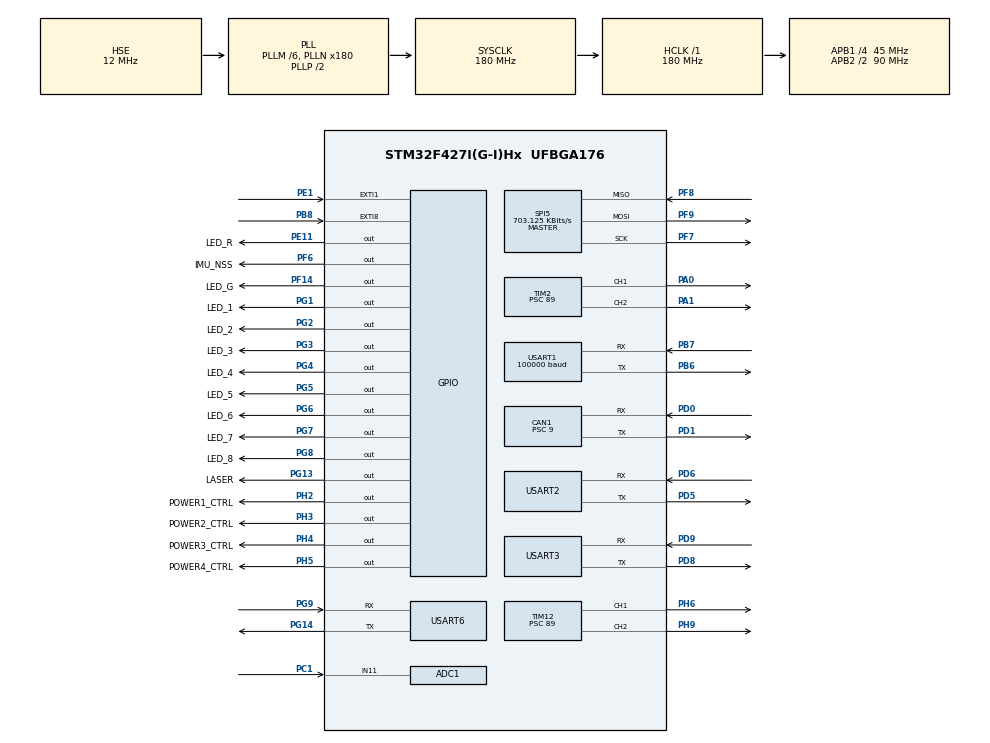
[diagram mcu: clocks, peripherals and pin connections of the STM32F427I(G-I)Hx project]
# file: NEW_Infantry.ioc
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ADC1.Channel-0\#ChannelRegularConversion=ADC_CHANNEL_11
ADC1.NbrOfConversionFlag=1
ADC1.Rank-0\#ChannelRegularConversion=1
ADC1.SamplingTime-0\#ChannelRegularConversion=ADC_SAMPLETIME_3CYCLES
ADC1.master=1
CAN1.BS1=CAN_BS1_2TQ
CAN1.BS2=CAN_BS2_2TQ
CAN1.CalculateTimeQuantum=200.0
CAN1.Prescaler=9
CAN1.TXFP=ENABLE
Dma.Request0=USART1_RX
Dma.Request1=USART3_RX
Dma.Request2=USART6_RX
Dma.Request3=USART6_TX
Dma.USART1_RX.0.Direction=DMA_PERIPH_TO_MEMORY
Dma.USART1_RX.0.FIFOMode=DMA_FIFOMODE_DISABLE
Dma.USART1_RX.0.Instance=DMA2_Stream2
Dma.USART1_RX.0.MemDataAlignment=DMA_MDATAALIGN_BYTE
Dma.USART1_RX.0.MemInc=DMA_MINC_ENABLE
Dma.USART1_RX.0.Mode=DMA_NORMAL
Dma.USART1_RX.0.PeriphDataAlignment=DMA_PDATAALIGN_BYTE
Dma.USART1_RX.0.PeriphInc=DMA_PINC_DISABLE
Dma.USART1_RX.0.Priority=DMA_PRIORITY_MEDIUM
Dma.USART3_RX.1.Direction=DMA_PERIPH_TO_MEMORY
Dma.USART3_RX.1.FIFOMode=DMA_FIFOMODE_DISABLE
Dma.USART3_RX.1.Instance=DMA1_Stream1
Dma.USART3_RX.1.MemDataAlignment=DMA_MDATAALIGN_BYTE
Dma.USART3_RX.1.MemInc=DMA_MINC_ENABLE
Dma.USART3_RX.1.Mode=DMA_NORMAL
Dma.USART3_RX.1.PeriphDataAlignment=DMA_PDATAALIGN_BYTE
Dma.USART3_RX.1.PeriphInc=DMA_PINC_DISABLE
Dma.USART3_RX.1.Priority=DMA_PRIORITY_LOW
Dma.USART6_RX.2.Direction=DMA_PERIPH_TO_MEMORY
Dma.USART6_RX.2.FIFOMode=DMA_FIFOMODE_DISABLE
Dma.USART6_RX.2.Instance=DMA2_Stream1
Dma.USART6_RX.2.MemDataAlignment=DMA_MDATAALIGN_BYTE
Dma.USART6_RX.2.MemInc=DMA_MINC_ENABLE
Dma.USART6_RX.2.Mode=DMA_NORMAL
Dma.USART6_RX.2.PeriphDataAlignment=DMA_PDATAALIGN_BYTE
Dma.USART6_RX.2.PeriphInc=DMA_PINC_DISABLE
Dma.USART6_RX.2.Priority=DMA_PRIORITY_LOW
Dma.USART6_TX.3.Direction=DMA_MEMORY_TO_PERIPH
Dma.USART6_TX.3.FIFOMode=DMA_FIFOMODE_DISABLE
Dma.USART6_TX.3.Instance=DMA2_Stream6
Dma.USART6_TX.3.MemDataAlignment=DMA_MDATAALIGN_BYTE
Dma.USART6_TX.3.MemInc=DMA_MINC_ENABLE
Dma.USART6_TX.3.Mode=DMA_NORMAL
Dma.USART6_TX.3.PeriphDataAlignment=DMA_PDATAALIGN_BYTE
Dma.USART6_TX.3.PeriphInc=DMA_PINC_DISABLE
Dma.USART6_TX.3.Priority=DMA_PRIORITY_LOW
FREERTOS.INCLUDE_vTaskDelayUntil=1
FREERTOS.Tasks01=defaultTask,0,128,StartDefaultTask,Default,NULL
FREERTOS.configUSE_TIMERS=0
Mcu.Family=STM32F4
Mcu.Name=STM32F427I(G-I)Hx
Mcu.Package=UFBGA176
NVIC.CAN1_RX0_IRQn=true\:4\:0\:true\:false\:true\:false\:true\:true
NVIC.DMA1_Stream1_IRQn=true\:5\:0\:false\:false\:true\:true\:false\:true
NVIC.DMA2_Stream1_IRQn=true\:5\:0\:false\:false\:true\:true\:false\:true
NVIC.DMA2_Stream2_IRQn=true\:5\:0\:false\:false\:true\:true\:false\:true
NVIC.DMA2_Stream6_IRQn=true\:5\:0\:false\:false\:true\:true\:false\:true
NVIC.EXTI1_IRQn=true\:6\:0\:true\:false\:true\:true\:true\:true
NVIC.EXTI9_5_IRQn=true\:6\:0\:true\:false\:true\:true\:true\:true
NVIC.PriorityGroup=NVIC_PRIORITYGROUP_4
NVIC.TIM8_TRG_COM_TIM14_IRQn=true\:0\:0\:false\:false\:true\:false\:false\:true
NVIC.TimeBase=TIM8_TRG_COM_TIM14_IRQn
NVIC.TimeBaseIP=TIM14
NVIC.USART1_IRQn=true\:6\:0\:true\:false\:true\:true\:true\:true
NVIC.USART3_IRQn=true\:7\:0\:true\:false\:true\:true\:true\:true
PA0/WKUP.Signal=S_TIM2_CH1_ETR
PA1.Signal=S_TIM2_CH2
PA13.Mode=Serial_Wire
PA13.Signal=SYS_JTMS-SWDIO
PA14.Mode=Serial_Wire
PA14.Signal=SYS_JTCK-SWCLK
PB6.Mode=Asynchronous
PB6.Signal=USART1_TX
PB7.Mode=Asynchronous
PB7.Signal=USART1_RX
PB8.GPIO_ModeDefaultEXTI=GPIO_MODE_IT_FALLING
PB8.Signal=GPXTI8
PC1.Signal=ADCx_IN11
PD0.Mode=Master
PD0.Signal=CAN1_RX
PD1.Mode=Master
PD1.Signal=CAN1_TX
PD5.Mode=Asynchronous
PD5.Signal=USART2_TX
PD6.Mode=Asynchronous
PD6.Signal=USART2_RX
PD8.Mode=Asynchronous
PD8.Signal=USART3_TX
PD9.Mode=Asynchronous
PD9.Signal=USART3_RX
PE1.GPIO_ModeDefaultEXTI=GPIO_MODE_IT_FALLING
PE1.Signal=GPXTI1
PE11.GPIO_Label=LED_R
PE11.GPIO_ModeDefaultOutputPP=GPIO_MODE_OUTPUT_PP
PE11.GPIO_PuPd=GPIO_NOPULL
PE11.GPIO_Speed=GPIO_SPEED_FREQ_VERY_HIGH
PE11.PinState=GPIO_PIN_SET
PE11.Signal=GPIO_Output
PF14.GPIO_Label=LED_G
PF14.GPIO_ModeDefaultOutputPP=GPIO_MODE_OUTPUT_PP
PF14.GPIO_PuPd=GPIO_NOPULL
PF14.GPIO_Speed=GPIO_SPEED_FREQ_VERY_HIGH
PF14.PinState=GPIO_PIN_SET
PF14.Signal=GPIO_Output
PF6.GPIO_Label=IMU_NSS
PF6.Signal=GPIO_Output
PF7.Mode=Full_Duplex_Master
PF7.Signal=SPI5_SCK
PF8.Mode=Full_Duplex_Master
PF8.Signal=SPI5_MISO
PF9.Mode=Full_Duplex_Master
PF9.Signal=SPI5_MOSI
PG1.GPIO_Label=LED_1
PG1.GPIO_ModeDefaultOutputPP=GPIO_MODE_OUTPUT_PP
PG1.GPIO_PuPd=GPIO_NOPULL
PG1.GPIO_Speed=GPIO_SPEED_FREQ_VERY_HIGH
PG1.PinState=GPIO_PIN_SET
PG1.Signal=GPIO_Output
PG13.GPIO_Label=LASER
PG13.GPIO_PuPd=GPIO_NOPULL
PG13.GPIO_Speed=GPIO_SPEED_FREQ_VERY_HIGH
PG13.Signal=GPIO_Output
PG14.Mode=Asynchronous
PG14.Signal=USART6_TX
PG2.GPIO_Label=LED_2
PG2.GPIO_ModeDefaultOutputPP=GPIO_MODE_OUTPUT_PP
PG2.GPIO_PuPd=GPIO_NOPULL
PG2.GPIO_Speed=GPIO_SPEED_FREQ_VERY_HIGH
PG2.PinState=GPIO_PIN_SET
PG2.Signal=GPIO_Output
PG3.GPIO_Label=LED_3
PG3.GPIO_ModeDefaultOutputPP=GPIO_MODE_OUTPUT_PP
PG3.GPIO_PuPd=GPIO_NOPULL
PG3.GPIO_Speed=GPIO_SPEED_FREQ_VERY_HIGH
PG3.PinState=GPIO_PIN_SET
PG3.Signal=GPIO_Output
PG4.GPIO_Label=LED_4
PG4.GPIO_ModeDefaultOutputPP=GPIO_MODE_OUTPUT_PP
PG4.GPIO_PuPd=GPIO_NOPULL
PG4.GPIO_Speed=GPIO_SPEED_FREQ_VERY_HIGH
PG4.PinState=GPIO_PIN_SET
PG4.Signal=GPIO_Output
PG5.GPIO_Label=LED_5
PG5.GPIO_ModeDefaultOutputPP=GPIO_MODE_OUTPUT_PP
PG5.GPIO_PuPd=GPIO_NOPULL
PG5.GPIO_Speed=GPIO_SPEED_FREQ_VERY_HIGH
PG5.PinState=GPIO_PIN_SET
PG5.Signal=GPIO_Output
PG6.GPIO_Label=LED_6
PG6.GPIO_ModeDefaultOutputPP=GPIO_MODE_OUTPUT_PP
PG6.GPIO_PuPd=GPIO_NOPULL
PG6.GPIO_Speed=GPIO_SPEED_FREQ_VERY_HIGH
PG6.PinState=GPIO_PIN_SET
PG6.Signal=GPIO_Output
PG7.GPIO_Label=LED_7
PG7.GPIO_ModeDefaultOutputPP=GPIO_MODE_OUTPUT_PP
PG7.GPIO_PuPd=GPIO_NOPULL
PG7.GPIO_Speed=GPIO_SPEED_FREQ_VERY_HIGH
PG7.PinState=GPIO_PIN_SET
PG7.Signal=GPIO_Output
PG8.GPIO_Label=LED_8
PG8.GPIO_ModeDefaultOutputPP=GPIO_MODE_OUTPUT_PP
PG8.GPIO_PuPd=GPIO_NOPULL
PG8.GPIO_Speed=GPIO_SPEED_FREQ_VERY_HIGH
PG8.PinState=GPIO_PIN_SET
PG8.Signal=GPIO_Output
PG9.Mode=Asynchronous
PG9.Signal=USART6_RX
PH0/OSC_IN.Mode=HSE-External-Oscillator
PH0/OSC_IN.Signal=RCC_OSC_IN
PH1/OSC_OUT.Mode=HSE-External-Oscillator
PH1/OSC_OUT.Signal=RCC_OSC_OUT
PH2.GPIO_Label=POWER1_CTRL
PH2.GPIO_ModeDefaultOutputPP=GPIO_MODE_OUTPUT_PP
PH2.GPIO_PuPd=GPIO_NOPULL
PH2.GPIO_Speed=GPIO_SPEED_FREQ_VERY_HIGH
PH2.PinState=GPIO_PIN_SET
PH2.Signal=GPIO_Output
PH3.GPIO_Label=POWER2_CTRL
PH3.GPIO_ModeDefaultOutputPP=GPIO_MODE_OUTPUT_PP
PH3.GPIO_PuPd=GPIO_NOPULL
PH3.GPIO_Speed=GPIO_SPEED_FREQ_VERY_HIGH
PH3.PinState=GPIO_PIN_SET
PH3.Signal=GPIO_Output
PH4.GPIO_Label=POWER3_CTRL
PH4.GPIO_ModeDefaultOutputPP=GPIO_MODE_OUTPUT_PP
PH4.GPIO_PuPd=GPIO_NOPULL
PH4.GPIO_Speed=GPIO_SPEED_FREQ_VERY_HIGH
PH4.PinState=GPIO_PIN_SET
PH4.Signal=GPIO_Output
PH5.GPIO_Label=POWER4_CTRL
PH5.GPIO_ModeDefaultOutputPP=GPIO_MODE_OUTPUT_PP
PH5.GPIO_PuPd=GPIO_NOPULL
PH5.GPIO_Speed=GPIO_SPEED_FREQ_VERY_HIGH
PH5.PinState=GPIO_PIN_SET
PH5.Signal=GPIO_Output
PH6.Signal=S_TIM12_CH1
PH9.Signal=S_TIM12_CH2
ProjectManager.HeapSize=0x500
ProjectManager.StackSize=0x800
ProjectManager.TargetToolchain=MDK-ARM V5
RCC.48MHZClocksFreq_Value=90000000
RCC.AHBFreq_Value=180000000
RCC.APB1CLKDivider=RCC_HCLK_DIV4
RCC.APB1Freq_Value=45000000
RCC.APB1TimFreq_Value=90000000
RCC.APB2CLKDivider=RCC_HCLK_DIV2
RCC.APB2Freq_Value=90000000
RCC.APB2TimFreq_Value=180000000
RCC.CortexFreq_Value=180000000
RCC.HCLKFreq_Value=180000000
RCC.HSE_VALUE=12000000
RCC.HSI_VALUE=16000000
RCC.LSE_VALUE=32768
RCC.PLLM=6
RCC.PLLN=180
RCC.PLLSourceVirtual=RCC_PLLSOURCE_HSE
RCC.SYSCLKFreq_VALUE=180000000
RCC.SYSCLKSource=RCC_SYSCLKSOURCE_PLLCLK
RCC.VCOOutputFreq_Value=360000000
SH.ADCx_IN11.0=ADC1_IN11,IN11
SH.S_TIM12_CH1.0=TIM12_CH1,PWM Generation1 CH1
SH.S_TIM12_CH2.0=TIM12_CH2,PWM Generation2 CH2
SH.S_TIM2_CH1_ETR.0=TIM2_CH1,PWM Generation1 CH1
SH.S_TIM2_CH2.0=TIM2_CH2,PWM Generation2 CH2
SPI5.BaudRatePrescaler=SPI_BAUDRATEPRESCALER_128
SPI5.CalculateBaudRate=703.125 KBits/s
SPI5.Direction=SPI_DIRECTION_2LINES
SPI5.Mode=SPI_MODE_MASTER
SPI5.VirtualType=VM_MASTER
TIM12.Channel-PWM\ Generation1\ CH1=TIM_CHANNEL_1
TIM12.Channel-PWM\ Generation2\ CH2=TIM_CHANNEL_2
TIM12.Period=19999
TIM12.Prescaler=89
TIM12.Pulse-PWM\ Generation1\ CH1=1000
TIM12.Pulse-PWM\ Generation2\ CH2=1000
TIM2.Channel-PWM\ Generation1\ CH1=TIM_CHANNEL_1
TIM2.Channel-PWM\ Generation2\ CH2=TIM_CHANNEL_2
TIM2.Period=19999
TIM2.Prescaler=89
TIM2.Pulse-PWM\ Generation1\ CH1=1000
TIM2.Pulse-PWM\ Generation2\ CH2=1000
TIM5.Period=0xffffffff
TIM5.Prescaler=899
TIM7.Period=65535
TIM7.Prescaler=8999
USART1.BaudRate=100000
USART1.VirtualMode=VM_ASYNC
USART2.VirtualMode=VM_ASYNC
USART3.VirtualMode=VM_ASYNC
USART6.VirtualMode=VM_ASYNC
VP_FREERTOS_VS_CMSIS_V1.Mode=CMSIS_V1
VP_SYS_VS_tim14.Mode=TIM14
VP_TIM12_VS_ClockSourceINT.Mode=Internal
VP_TIM2_VS_ClockSourceINT.Mode=Internal
VP_TIM5_VS_ClockSourceINT.Mode=Internal
VP_TIM7_VS_ClockSourceINT.Mode=Enable_Timer
board=custom

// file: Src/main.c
/* USER CODE BEGIN Header */
/**
  ******************************************************************************
  * @file           : main.c
  * @brief          : Main program body
  ******************************************************************************
  * @attention
  *
  * <h2><center>&copy; Copyright (c) 2019 STMicroelectronics.
  * All rights reserved.</center></h2>
  *
  * This software component is licensed by ST under Ultimate Liberty license
  * SLA0044, the "License"; You may not use this file except in compliance with
  * the License. You may obtain a copy of the License at:
  *                             www.st.com/SLA0044
  *
  ******************************************************************************
  */
/* USER CODE END Header */

#include "main.h"
#include "cmsis_os.h"
#include "adc.h"
#include "can.h"
#include "dma.h"
#include "spi.h"
#include "tim.h"
#include "usart.h"
#include "gpio.h"

void SystemClock_Config(void);
void MX_FREERTOS_Init(void);

int main(void)
{

  /* MCU Configuration--------------------------------------------------------*/

  /* Reset of all peripherals, Initializes the Flash interface and the Systick. */
  HAL_Init();

  /* Configure the system clock */
  SystemClock_Config();

  /* Initialize all configured peripherals */
  MX_GPIO_Init();
  MX_DMA_Init();
  MX_CAN1_Init();
  MX_SPI5_Init();
  MX_TIM2_Init();
  MX_USART1_UART_Init();
  MX_USART2_UART_Init();
  MX_TIM7_Init();
  MX_TIM5_Init();
  MX_USART3_UART_Init();
  MX_TIM12_Init();
  MX_ADC1_Init();
  MX_USART6_UART_Init();

  /* Call init function for freertos objects (in freertos.c) */
  MX_FREERTOS_Init();

  /* Start scheduler */
  osKernelStart();

  /* We should never get here as control is now taken by the scheduler */

  /* Infinite loop */
  while (1)
  {

  }
}

void SystemClock_Config(void)
{
  RCC_OscInitTypeDef RCC_OscInitStruct = {0};
  RCC_ClkInitTypeDef RCC_ClkInitStruct = {0};

  /** Configure the main internal regulator output voltage
  */
  __HAL_RCC_PWR_CLK_ENABLE();
  __HAL_PWR_VOLTAGESCALING_CONFIG(PWR_REGULATOR_VOLTAGE_SCALE1);
  /** Initializes the CPU, AHB and APB busses clocks
  */
  RCC_OscInitStruct.OscillatorType = RCC_OSCILLATORTYPE_HSE;
  RCC_OscInitStruct.HSEState = RCC_HSE_ON;
  RCC_OscInitStruct.PLL.PLLState = RCC_PLL_ON;
  RCC_OscInitStruct.PLL.PLLSource = RCC_PLLSOURCE_HSE;
  RCC_OscInitStruct.PLL.PLLM = 6;
  RCC_OscInitStruct.PLL.PLLN = 180;
  RCC_OscInitStruct.PLL.PLLP = RCC_PLLP_DIV2;
  RCC_OscInitStruct.PLL.PLLQ = 4;
  if (HAL_RCC_OscConfig(&RCC_OscInitStruct) != HAL_OK)
  {
    Error_Handler();
  }
  /** Activate the Over-Drive mode
  */
  if (HAL_PWREx_EnableOverDrive() != HAL_OK)
  {
    Error_Handler();
  }
  /** Initializes the CPU, AHB and APB busses clocks
  */
  RCC_ClkInitStruct.ClockType = RCC_CLOCKTYPE_HCLK|RCC_CLOCKTYPE_SYSCLK
                              |RCC_CLOCKTYPE_PCLK1|RCC_CLOCKTYPE_PCLK2;
  RCC_ClkInitStruct.SYSCLKSource = RCC_SYSCLKSOURCE_PLLCLK;
  RCC_ClkInitStruct.AHBCLKDivider = RCC_SYSCLK_DIV1;
  RCC_ClkInitStruct.APB1CLKDivider = RCC_HCLK_DIV4;
  RCC_ClkInitStruct.APB2CLKDivider = RCC_HCLK_DIV2;

  if (HAL_RCC_ClockConfig(&RCC_ClkInitStruct, FLASH_LATENCY_5) != HAL_OK)
  {
    Error_Handler();
  }
}

void HAL_TIM_PeriodElapsedCallback(TIM_HandleTypeDef *htim)
{
  if (htim->Instance == TIM14) {
    HAL_IncTick();
  }
}

void Error_Handler(void)
{
}

/************************ (C) COPYRIGHT STMicroelectronics *****END OF FILE****/

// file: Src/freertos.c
/* USER CODE BEGIN Header */
/**
  ******************************************************************************
  * File Name          : freertos.c
  * Description        : Code for freertos applications
  ******************************************************************************
  * @attention
  *
  * <h2><center>&copy; Copyright (c) 2019 STMicroelectronics.
  * All rights reserved.</center></h2>
  *
  * This software component is licensed by ST under Ultimate Liberty license
  * SLA0044, the "License"; You may not use this file except in compliance with
  * the License. You may obtain a copy of the License at:
  *                             www.st.com/SLA0044
  *
  ******************************************************************************
  */
/* USER CODE END Header */

#include "FreeRTOS.h"
#include "task.h"
#include "main.h"
#include "cmsis_os.h"

/* USER CODE BEGIN Includes */
#include "freertos_task.h"
/* USER CODE END Includes */

osThreadId defaultTaskHandle;

void StartDefaultTask(void const * argument);

void MX_FREERTOS_Init(void); /* (MISRA C 2004 rule 8.1) */

/* GetIdleTaskMemory prototype (linked to static allocation support) */
void vApplicationGetIdleTaskMemory( StaticTask_t **ppxIdleTaskTCBBuffer, StackType_t **ppxIdleTaskStackBuffer, uint32_t *pulIdleTaskStackSize );

/* USER CODE BEGIN GET_IDLE_TASK_MEMORY */
static StaticTask_t xIdleTaskTCBBuffer;
static StackType_t xIdleStack[configMINIMAL_STACK_SIZE];

void vApplicationGetIdleTaskMemory( StaticTask_t **ppxIdleTaskTCBBuffer, StackType_t **ppxIdleTaskStackBuffer, uint32_t *pulIdleTaskStackSize )
{
  *ppxIdleTaskTCBBuffer = &xIdleTaskTCBBuffer;
  *ppxIdleTaskStackBuffer = &xIdleStack[0];
  *pulIdleTaskStackSize = configMINIMAL_STACK_SIZE;
  /* place for user code */
}
/* USER CODE END GET_IDLE_TASK_MEMORY */

void MX_FREERTOS_Init(void) {

  /* Create the thread(s) */
  /* definition and creation of defaultTask */
  osThreadDef(defaultTask, StartDefaultTask, osPriorityNormal, 0, 128);
  defaultTaskHandle = osThreadCreate(osThread(defaultTask), NULL);

}

void StartDefaultTask(void const * argument)
{

  /* USER CODE BEGIN StartDefaultTask */
	taskENTER_CRITICAL();
	StartTask();
	vTaskDelete(NULL);
	taskEXIT_CRITICAL();
  /* Infinite loop */
  for(;;)
  {
    osDelay(1);
  }
  /* USER CODE END StartDefaultTask */
}

/************************ (C) COPYRIGHT STMicroelectronics *****END OF FILE****/
